# ATSAME51J18A register map
Vendor: Microchip Technology; Series: SAME51; File version: 0
CPU: CM4 r0p1, selectable endian, MPU, FPU, 3 interrupt priority bits
Registers are 32-bit, read-write, reset 0x0 unless marked. A register's access mark holds for its fields unless they carry their own. Offsets are from the block's base; [hi:lo] are bit positions; {n}, {i} and the like mark numbered series; 'fields as' and 'values as' point back to an identical list.

## SDHC0 — SD/MMC Host Controller
Base 0x45000000; register names take the prefix SDHC_
0x00 SSAR — SDMA System Address / Argument 2
  [31:0] ADDR — SDMA System Address
0x00 SSAR_CMD23_MODE (alternate view of SSAR) — SDMA System Address / Argument 2
  [31:0] ARG2 — Argument 2
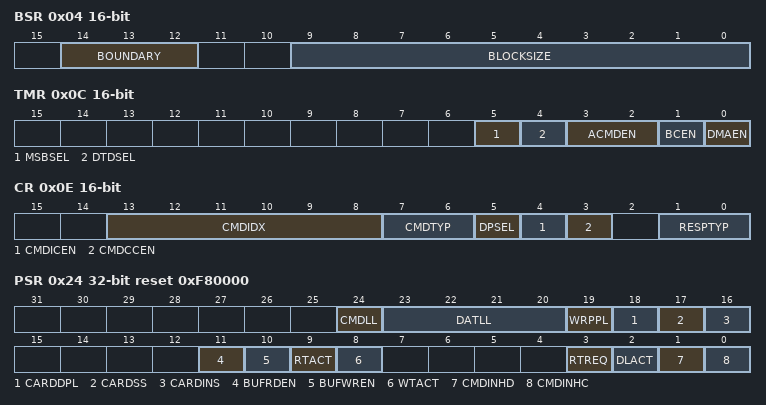
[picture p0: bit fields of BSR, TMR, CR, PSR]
0x04 BSR 16-bit — Block Size
  [14:12] BOUNDARY — SDMA Buffer Boundary
    0=4K (4k bytes); 1=8K (8k bytes); 2=16K (16k bytes); 3=32K (32k bytes); 4=64K (64k bytes); 5=128K (128k bytes); 6=256K (256k bytes); 7=512K (512k bytes)
  [9:0] BLOCKSIZE — Transfer Block Size
0x06 BCR 16-bit — Block Count
  [15:0] BCNT — Blocks Count for Current Transfer
0x08 ARG1R — Argument 1
  [31:0] ARG
0x0C TMR 16-bit — Transfer Mode
  [5] MSBSEL — Multi/Single Block Selection
    0=SINGLE (Single Block); 1=MULTIPLE (Multiple Block)
  [4] DTDSEL — Data Transfer Direction Selection
    0=WRITE (Write (Host to Card)); 1=READ (Read (Card to Host))
  [3:2] ACMDEN — Auto Command Enable
    0=DISABLED (Auto Command Disabled); 1=CMD12 (Auto CMD12 Enable); 2=CMD23 (Auto CMD23 Enable)
  [1] BCEN — Block Count Enable
    0=DISABLE; 1=ENABLE
  [0] DMAEN — DMA Enable
    0=DISABLE (No data transfer or Non DMA data transfer); 1=ENABLE (DMA data transfer)
0x0E CR 16-bit — Command
  [13:8] CMDIDX — Command Index
  [7:6] CMDTYP — Command Type
    0=NORMAL (Other commands); 1=SUSPEND (CMD52 for writing Bus Suspend in CCCR); 2=RESUME (CMD52 for writing Function Select in CCCR); 3=ABORT (CMD12, CMD52 for writing I/O Abort in CCCR)
  [5] DPSEL — Data Present Select
    0=NO_DATA (No Data Present); 1=DATA (Data Present)
  [4] CMDICEN — Command Index Check Enable
    0=DISABLE; 1=ENABLE
  [3] CMDCCEN — Command CRC Check Enable
    0=DISABLE; 1=ENABLE
  [1:0] RESPTYP — Response Type
    0=NONE (No response); 1=136_BIT (136-bit response); 2=48_BIT (48-bit response); 3=48_BIT_BUSY (48-bit response check busy after response)
{0x10+4i} RR[{i}] (i=0..3) ro — Response
  [31:0] CMDRESP — Command Response
0x20 BDPR — Buffer Data Port
  [31:0] BUFDATA — Buffer Data
0x24 PSR ro reset 0xF80000 — Present State
  [24] CMDLL — CMD Line Level
  [23:20] DATLL — DAT[3:0] Line Level
  [19] WRPPL — Write Protect Pin Level
    0=PROTECTED (Write protected (SDWP#=0)); 1=ENABLED (Write enabled (SDWP#=1))
  [18] CARDDPL — Card Detect Pin Level
    0=NO (No card present (SDCD#=1)); 1=YES (Card present (SDCD#=0))
  [17] CARDSS — Card State Stable
    0=NO (Reset or Debouncing); 1=YES (No Card or Insered)
  [16] CARDINS — Card Inserted
    0=NO (Reset or Debouncing or No Card); 1=YES (Card inserted)
  [11] BUFRDEN — Buffer Read Enable
    0=DISABLE (Read disable); 1=ENABLE (Read enable)
  [10] BUFWREN — Buffer Write Enable
    0=DISABLE (Write disable); 1=ENABLE (Write enable)
  [9] RTACT — Read Transfer Active
    0=NO (No valid data); 1=YES (Transferring data)
  [8] WTACT — Write Transfer Active
    0=NO (No valid data); 1=YES (Transferring data)
  [3] RTREQ — Re-Tuning Request
    0=OK (Fixed or well-tuned sampling clock); 1=REQUIRED (Sampling clock needs re-tuning)
  [2] DLACT — DAT Line Active
    0=INACTIVE (DAT Line Inactive); 1=ACTIVE (DAT Line Active)
  [1] CMDINHD — Command Inhibit (DAT)
    0=CAN (Can issue command which uses the DAT line); 1=CANNOT (Cannot issue command which uses the DAT line)
  [0] CMDINHC — Command Inhibit (CMD)
    0=CAN (Can issue command using only CMD line); 1=CANNOT (Cannot issue command)
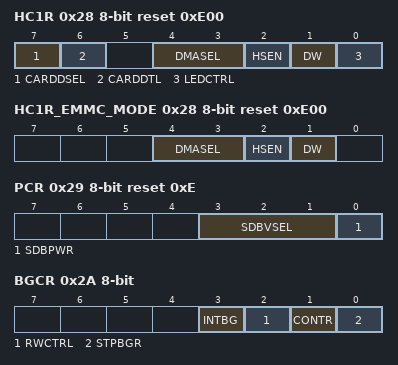
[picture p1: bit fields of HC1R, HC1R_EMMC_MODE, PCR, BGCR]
0x28 HC1R 8-bit reset 0xE00 — Host Control 1
  [7] CARDDSEL — Card Detect Signal Selection
    0=NORMAL (SDCD# is selected (for normal use)); 1=TEST (The Card Select Test Level is selected (for test purpose))
  [6] CARDDTL — Card Detect Test Level
    0=NO (No Card); 1=YES (Card Inserted)
  [4:3] DMASEL — DMA Select
    0=SDMA (SDMA is selected); 2=32BIT (32-bit Address ADMA2 is selected)
  [2] HSEN — High Speed Enable
    0=NORMAL (Normal Speed mode); 1=HIGH (High Speed mode)
  [1] DW — Data Width
    0=1BIT (1-bit mode); 1=4BIT (4-bit mode)
  [0] LEDCTRL — LED Control
    0=OFF (LED off); 1=ON (LED on)
0x28 HC1R_EMMC_MODE 8-bit reset 0xE00 (alternate view of HC1R) — Host Control 1
  [4:3] DMASEL — DMA Select
    values as HC1R.DMASEL
  [2] HSEN — High Speed Enable
    0=NORMAL (Normal Speed mode); 1=HIGH (High Speed mode)
  [1] DW — Data Width
    0=1BIT (1-bit mode); 1=4BIT (4-bit mode)
0x29 PCR 8-bit reset 0xE — Power Control
  [3:1] SDBVSEL — SD Bus Voltage Select
    5=1V8 (1.8V (Typ.)); 6=3V0 (3.0V (Typ.)); 7=3V3 (3.3V (Typ.))
  [0] SDBPWR — SD Bus Power
    0=OFF (Power off); 1=ON (Power on)
0x2A BGCR 8-bit — Block Gap Control
  [3] INTBG — Interrupt at Block Gap
    0=DISABLED; 1=ENABLED
  [2] RWCTRL — Read Wait Control
    0=DISABLE (Disable Read Wait Control); 1=ENABLE (Enable Read Wait Control)
  [1] CONTR — Continue Request
    0=GO_ON (Not affected); 1=RESTART
  [0] STPBGR — Stop at Block Gap Request
    0=TRANSFER; 1=STOP
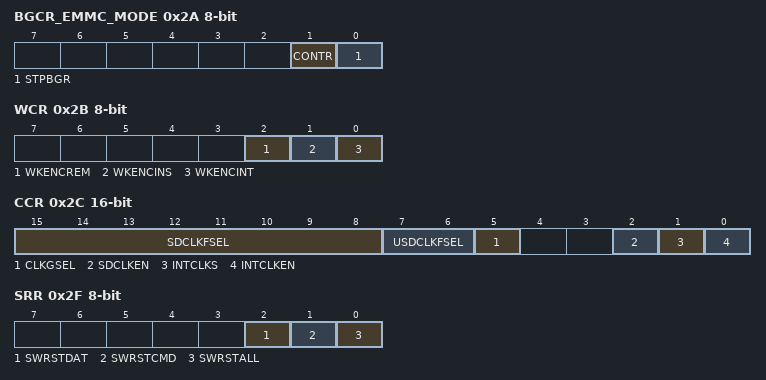
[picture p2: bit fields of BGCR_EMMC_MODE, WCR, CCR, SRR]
0x2A BGCR_EMMC_MODE 8-bit (alternate view of BGCR) — Block Gap Control
  [1] CONTR — Continue Request
    0=GO_ON (Not affected); 1=RESTART
  [0] STPBGR — Stop at Block Gap Request
    0=TRANSFER; 1=STOP
0x2B WCR 8-bit — Wakeup Control
  [all] fields
    0=DISABLE; 1=ENABLE
  [2] WKENCREM — Wakeup Event Enable on Card Removal
  [1] WKENCINS — Wakeup Event Enable on Card Insertion
  [0] WKENCINT — Wakeup Event Enable on Card Interrupt
0x2C CCR 16-bit — Clock Control
  [15:8] SDCLKFSEL — SDCLK Frequency Select
  [7:6] USDCLKFSEL — Upper Bits of SDCLK Frequency Select
  [5] CLKGSEL — Clock Generator Select
    0=DIV (Divided Clock Mode); 1=PROG (Programmable Clock Mode)
  [2] SDCLKEN — SD Clock Enable
    0=DISABLE; 1=ENABLE
  [1] INTCLKS — Internal Clock Stable
    0=NOT_READY; 1=READY
  [0] INTCLKEN — Internal Clock Enable
    0=OFF (Stop); 1=ON (Oscillate)
0x2E TCR 8-bit — Timeout Control
  [3:0] DTCVAL — Data Timeout Counter Value
0x2F SRR 8-bit — Software Reset
  [all] fields
    0=WORK; 1=RESET
  [2] SWRSTDAT — Software Reset For DAT Line
  [1] SWRSTCMD — Software Reset For CMD Line
  [0] SWRSTALL — Software Reset For All
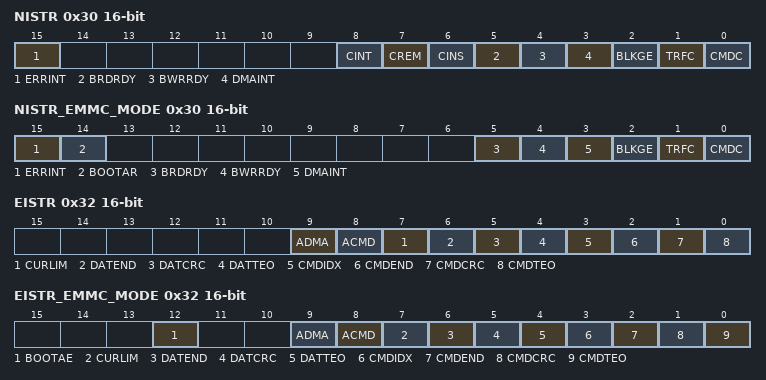
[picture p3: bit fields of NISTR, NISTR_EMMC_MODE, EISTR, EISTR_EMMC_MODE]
0x30 NISTR 16-bit — Normal Interrupt Status
  [15] ERRINT ro — Error Interrupt
    0=NO (No Error); 1=YES (Error)
  [8] CINT — Card Interrupt
    0=NO (No Card Interrupt); 1=YES (Generate Card Interrupt)
  [7] CREM write-1-clears — Card Removal
    0=NO (Card state stable or Debouncing); 1=YES (Card Removed)
  [6] CINS write-1-clears — Card Insertion
    0=NO (Card state stable or Debouncing); 1=YES (Card inserted)
  [5] BRDRDY write-1-clears — Buffer Read Ready
    0=NO (Not ready to read buffer); 1=YES (Ready to read buffer)
  [4] BWRRDY write-1-clears — Buffer Write Ready
    0=NO (Not ready to write buffer); 1=YES (Ready to write buffer)
  [3] DMAINT write-1-clears — DMA Interrupt
    0=NO (No DMA Interrupt); 1=YES (DMA Interrupt is generated)
  [2] BLKGE write-1-clears — Block Gap Event
    0=NO (No Block Gap Event); 1=STOP (Transaction stopped at block gap)
  [1] TRFC write-1-clears — Transfer Complete
    0=NO (Not complete); 1=YES (Command execution is completed)
  [0] CMDC write-1-clears — Command Complete
    0=NO (No command complete); 1=YES (Command complete)
0x30 NISTR_EMMC_MODE 16-bit (alternate view of NISTR) — Normal Interrupt Status
  [15] ERRINT ro — Error Interrupt
    0=NO (No Error); 1=YES (Error)
  [14] BOOTAR write-1-clears — Boot Acknowledge Received
  [5] BRDRDY write-1-clears — Buffer Read Ready
    values as NISTR.BRDRDY
  [4] BWRRDY write-1-clears — Buffer Write Ready
    values as NISTR.BWRRDY
  [3] DMAINT write-1-clears — DMA Interrupt
    0=NO (No DMA Interrupt); 1=YES (DMA Interrupt is generated)
  [2] BLKGE write-1-clears — Block Gap Event
    values as NISTR.BLKGE
  [1] TRFC write-1-clears — Transfer Complete
    0=NO (Not complete); 1=YES (Command execution is completed)
  [0] CMDC write-1-clears — Command Complete
    0=NO (No command complete); 1=YES (Command complete)
0x32 EISTR 16-bit — Error Interrupt Status
  [9] ADMA write-1-clears — ADMA Error
    0=NO (No Error); 1=YES (Error)
  [8] ACMD write-1-clears — Auto CMD Error
    0=NO (No Error); 1=YES (Error)
  [7] CURLIM write-1-clears — Current Limit Error
    0=NO (No Error); 1=YES (Power Fail)
  [6] DATEND write-1-clears — Data End Bit Error
    0=NO (No Error); 1=YES (Error)
  [5] DATCRC write-1-clears — Data CRC Error
    0=NO (No Error); 1=YES (Error)
  [4] DATTEO write-1-clears — Data Timeout Error
    0=NO (No Error); 1=YES (Timeout)
  [3] CMDIDX write-1-clears — Command Index Error
    0=NO (No Error); 1=YES (Error)
  [2] CMDEND write-1-clears — Command End Bit Error
    0=NO (No error); 1=YES (End Bit Error Generated)
  [1] CMDCRC write-1-clears — Command CRC Error
    0=NO (No Error); 1=YES (CRC Error Generated)
  [0] CMDTEO write-1-clears — Command Timeout Error
    0=NO (No Error); 1=YES (Timeout)
0x32 EISTR_EMMC_MODE 16-bit (alternate view of EISTR) — Error Interrupt Status
  [12] BOOTAE write-1-clears — Boot Acknowledge Error
    0=FIFO contains at least one byte; 1=FIFO is empty
  [9] ADMA write-1-clears — ADMA Error
    0=NO (No Error); 1=YES (Error)
  [8] ACMD write-1-clears — Auto CMD Error
    0=NO (No Error); 1=YES (Error)
  [7] CURLIM write-1-clears — Current Limit Error
    0=NO (No Error); 1=YES (Power Fail)
  [6] DATEND write-1-clears — Data End Bit Error
    0=NO (No Error); 1=YES (Error)
  [5] DATCRC write-1-clears — Data CRC Error
    0=NO (No Error); 1=YES (Error)
  [4] DATTEO write-1-clears — Data Timeout Error
    0=NO (No Error); 1=YES (Timeout)
  [3] CMDIDX write-1-clears — Command Index Error
    0=NO (No Error); 1=YES (Error)
  [2] CMDEND write-1-clears — Command End Bit Error
    0=NO (No error); 1=YES (End Bit Error Generated)
  [1] CMDCRC write-1-clears — Command CRC Error
    0=NO (No Error); 1=YES (CRC Error Generated)
  [0] CMDTEO write-1-clears — Command Timeout Error
    0=NO (No Error); 1=YES (Timeout)
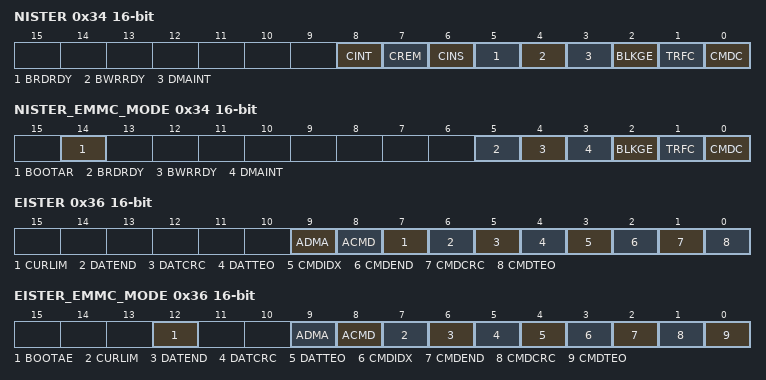
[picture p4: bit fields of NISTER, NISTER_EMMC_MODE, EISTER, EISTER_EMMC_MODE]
0x34 NISTER 16-bit — Normal Interrupt Status Enable
  [all] fields
    0=MASKED; 1=ENABLED
  [8] CINT — Card Interrupt Status Enable
  [7] CREM — Card Removal Status Enable
  [6] CINS — Card Insertion Status Enable
  [5] BRDRDY — Buffer Read Ready Status Enable
  [4] BWRRDY — Buffer Write Ready Status Enable
  [3] DMAINT — DMA Interrupt Status Enable
  [2] BLKGE — Block Gap Event Status Enable
  [1] TRFC — Transfer Complete Status Enable
  [0] CMDC — Command Complete Status Enable
0x34 NISTER_EMMC_MODE 16-bit (alternate view of NISTER) — Normal Interrupt Status Enable
  [14] BOOTAR — Boot Acknowledge Received Status Enable
  [5] BRDRDY — Buffer Read Ready Status Enable
    0=MASKED; 1=ENABLED
  [4] BWRRDY — Buffer Write Ready Status Enable
    0=MASKED; 1=ENABLED
  [3] DMAINT — DMA Interrupt Status Enable
    0=MASKED; 1=ENABLED
  [2] BLKGE — Block Gap Event Status Enable
    0=MASKED; 1=ENABLED
  [1] TRFC — Transfer Complete Status Enable
    0=MASKED; 1=ENABLED
  [0] CMDC — Command Complete Status Enable
    0=MASKED; 1=ENABLED
0x36 EISTER 16-bit — Error Interrupt Status Enable
  [all] fields
    0=MASKED; 1=ENABLED
  [9] ADMA — ADMA Error Status Enable
  [8] ACMD — Auto CMD Error Status Enable
  [7] CURLIM — Current Limit Error Status Enable
  [6] DATEND — Data End Bit Error Status Enable
  [5] DATCRC — Data CRC Error Status Enable
  [4] DATTEO — Data Timeout Error Status Enable
  [3] CMDIDX — Command Index Error Status Enable
  [2] CMDEND — Command End Bit Error Status Enable
  [1] CMDCRC — Command CRC Error Status Enable
  [0] CMDTEO — Command Timeout Error Status Enable
0x36 EISTER_EMMC_MODE 16-bit (alternate view of EISTER) — Error Interrupt Status Enable
  [12] BOOTAE — Boot Acknowledge Error Status Enable
  [9] ADMA — ADMA Error Status Enable
    0=MASKED; 1=ENABLED
  [8] ACMD — Auto CMD Error Status Enable
    0=MASKED; 1=ENABLED
  [7] CURLIM — Current Limit Error Status Enable
    0=MASKED; 1=ENABLED
  [6] DATEND — Data End Bit Error Status Enable
    0=MASKED; 1=ENABLED
  [5] DATCRC — Data CRC Error Status Enable
    0=MASKED; 1=ENABLED
  [4] DATTEO — Data Timeout Error Status Enable
    0=MASKED; 1=ENABLED
  [3] CMDIDX — Command Index Error Status Enable
    0=MASKED; 1=ENABLED
  [2] CMDEND — Command End Bit Error Status Enable
    0=MASKED; 1=ENABLED
  [1] CMDCRC — Command CRC Error Status Enable
    0=MASKED; 1=ENABLED
  [0] CMDTEO — Command Timeout Error Status Enable
    0=MASKED; 1=ENABLED
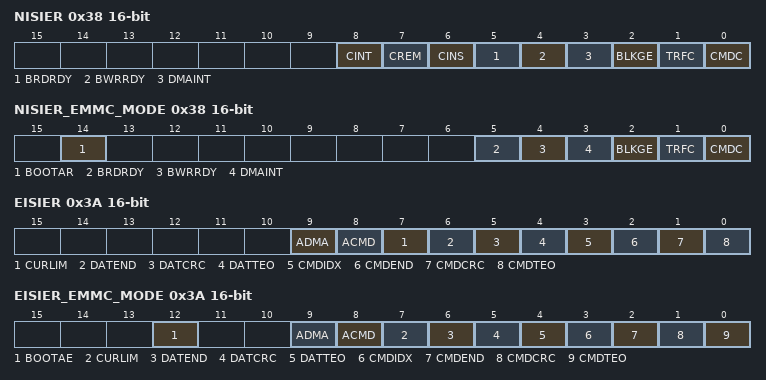
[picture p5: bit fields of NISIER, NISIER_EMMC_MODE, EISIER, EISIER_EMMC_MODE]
0x38 NISIER 16-bit — Normal Interrupt Signal Enable
  [all] fields
    0=MASKED; 1=ENABLED
  [8] CINT — Card Interrupt Signal Enable
  [7] CREM — Card Removal Signal Enable
  [6] CINS — Card Insertion Signal Enable
  [5] BRDRDY — Buffer Read Ready Signal Enable
  [4] BWRRDY — Buffer Write Ready Signal Enable
  [3] DMAINT — DMA Interrupt Signal Enable
  [2] BLKGE — Block Gap Event Signal Enable
  [1] TRFC — Transfer Complete Signal Enable
  [0] CMDC — Command Complete Signal Enable
0x38 NISIER_EMMC_MODE 16-bit (alternate view of NISIER) — Normal Interrupt Signal Enable
  [14] BOOTAR — Boot Acknowledge Received Signal Enable
  [5] BRDRDY — Buffer Read Ready Signal Enable
    0=MASKED; 1=ENABLED
  [4] BWRRDY — Buffer Write Ready Signal Enable
    0=MASKED; 1=ENABLED
  [3] DMAINT — DMA Interrupt Signal Enable
    0=MASKED; 1=ENABLED
  [2] BLKGE — Block Gap Event Signal Enable
    0=MASKED; 1=ENABLED
  [1] TRFC — Transfer Complete Signal Enable
    0=MASKED; 1=ENABLED
  [0] CMDC — Command Complete Signal Enable
    0=MASKED; 1=ENABLED
0x3A EISIER 16-bit — Error Interrupt Signal Enable
  [all] fields
    0=MASKED; 1=ENABLED
  [9] ADMA — ADMA Error Signal Enable
  [8] ACMD — Auto CMD Error Signal Enable
  [7] CURLIM — Current Limit Error Signal Enable
  [6] DATEND — Data End Bit Error Signal Enable
  [5] DATCRC — Data CRC Error Signal Enable
  [4] DATTEO — Data Timeout Error Signal Enable
  [3] CMDIDX — Command Index Error Signal Enable
  [2] CMDEND — Command End Bit Error Signal Enable
  [1] CMDCRC — Command CRC Error Signal Enable
  [0] CMDTEO — Command Timeout Error Signal Enable
0x3A EISIER_EMMC_MODE 16-bit (alternate view of EISIER) — Error Interrupt Signal Enable
  [12] BOOTAE — Boot Acknowledge Error Signal Enable
  [9] ADMA — ADMA Error Signal Enable
    0=MASKED; 1=ENABLED
  [8] ACMD — Auto CMD Error Signal Enable
    0=MASKED; 1=ENABLED
  [7] CURLIM — Current Limit Error Signal Enable
    0=MASKED; 1=ENABLED
  [6] DATEND — Data End Bit Error Signal Enable
    0=MASKED; 1=ENABLED
  [5] DATCRC — Data CRC Error Signal Enable
    0=MASKED; 1=ENABLED
  [4] DATTEO — Data Timeout Error Signal Enable
    0=MASKED; 1=ENABLED
  [3] CMDIDX — Command Index Error Signal Enable
    0=MASKED; 1=ENABLED
  [2] CMDEND — Command End Bit Error Signal Enable
    0=MASKED; 1=ENABLED
  [1] CMDCRC — Command CRC Error Signal Enable
    0=MASKED; 1=ENABLED
  [0] CMDTEO — Command Timeout Error Signal Enable
    0=MASKED; 1=ENABLED
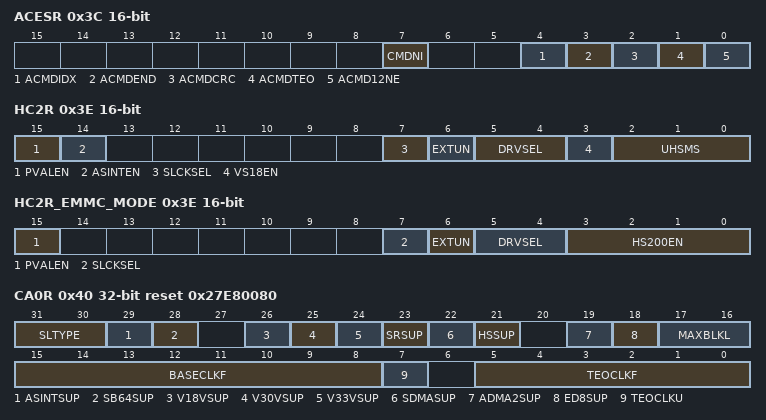
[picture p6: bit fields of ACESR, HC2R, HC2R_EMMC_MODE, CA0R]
0x3C ACESR 16-bit ro — Auto CMD Error Status
  [7] CMDNI — Command not Issued By Auto CMD12 Error
    0=OK (No error); 1=NOT_ISSUED
  [4] ACMDIDX — Auto CMD Index Error
    0=NO (No error); 1=YES (Error)
  [3] ACMDEND — Auto CMD End Bit Error
    0=NO (No error); 1=YES (End Bit Error Generated)
  [2] ACMDCRC — Auto CMD CRC Error
    0=NO (No error); 1=YES (CRC Error Generated)
  [1] ACMDTEO — Auto CMD Timeout Error
    0=NO (No error); 1=YES (Timeout)
  [0] ACMD12NE — Auto CMD12 Not Executed
    0=EXEC (Executed); 1=NOT_EXEC (Not executed)
0x3E HC2R 16-bit — Host Control 2
  [15] PVALEN — Preset Value Enable
    0=HOST (SDCLK and Driver Strength are controlled by Host Controller); 1=AUTO (Automatic Selection by Preset Value is Enabled)
  [14] ASINTEN — Asynchronous Interrupt Enable
    0=DISABLED; 1=ENABLED
  [7] SLCKSEL — Sampling Clock Select
    0=FIXED (Fixed clock is used to sample data); 1=TUNED (Tuned clock is used to sample data)
  [6] EXTUN — Execute Tuning
    0=NO (Not Tuned or Tuning Completed); 1=REQUESTED (Execute Tuning)
  [5:4] DRVSEL — Driver Strength Select
    0=B (Driver Type B is Selected (Default)); 1=A (Driver Type A is Selected); 2=C (Driver Type C is Selected); 3=D (Driver Type D is Selected)
  [3] VS18EN — 1.8V Signaling Enable
    0=S33V (3.3V Signaling); 1=S18V (1.8V Signaling)
  [2:0] UHSMS — UHS Mode Select
    0=SDR12; 1=SDR25; 2=SDR50; 3=SDR104; 4=DDR50
0x3E HC2R_EMMC_MODE 16-bit (alternate view of HC2R) — Host Control 2
  [15] PVALEN — Preset Value Enable
    values as HC2R.PVALEN
  [7] SLCKSEL — Sampling Clock Select
    values as HC2R.SLCKSEL
  [6] EXTUN — Execute Tuning
    values as HC2R.EXTUN
  [5:4] DRVSEL — Driver Strength Select
    values as HC2R.DRVSEL
  [3:0] HS200EN — HS200 Mode Enable
    0=SDR12; 1=SDR25; 2=SDR50; 3=SDR104; 4=DDR50
0x40 CA0R ro reset 0x27E80080 — Capabilities 0
  [31:30] SLTYPE — Slot Type
    0=REMOVABLE (Removable Card Slot); 1=EMBEDDED (Embedded Slot for One Device)
  [29] ASINTSUP — Asynchronous Interrupt Support
    0=NO (Asynchronous Interrupt not Supported); 1=YES (Asynchronous Interrupt supported)
  [28] SB64SUP — 64-Bit System Bus Support
    0=NO (32-bit Address Descriptors and System Bus); 1=YES (64-bit Address Descriptors and System Bus)
  [26] V18VSUP — Voltage Support 1.8V
    0=NO (1.8V Not Supported); 1=YES (1.8V Supported)
  [25] V30VSUP — Voltage Support 3.0V
    0=NO (3.0V Not Supported); 1=YES (3.0V Supported)
  [24] V33VSUP — Voltage Support 3.3V
    0=NO (3.3V Not Supported); 1=YES (3.3V Supported)
  [23] SRSUP — Suspend/Resume Support
    0=NO (Suspend/Resume not Supported); 1=YES (Suspend/Resume Supported)
  [22] SDMASUP — SDMA Support
    0=NO (SDMA not Supported); 1=YES (SDMA Supported)
  [21] HSSUP — High Speed Support
    0=NO (High Speed not Supported); 1=YES (High Speed Supported)
  [19] ADMA2SUP — ADMA2 Support
    0=NO (ADMA2 not Supported); 1=YES (ADMA2 Supported)
  [18] ED8SUP — 8-bit Support for Embedded Device
    0=NO (8-bit Bus Width not Supported); 1=YES (8-bit Bus Width Supported)
  [17:16] MAXBLKL — Max Block Length
    0=512 bytes; 1=1024 bytes; 2=2048 bytes
  [15:8] BASECLKF — Base Clock Frequency
    0=OTHER (Get information via another method)
  [7] TEOCLKU — Timeout Clock Unit
    0=KHZ; 1=MHZ
  [5:0] TEOCLKF — Timeout Clock Frequency
    0=OTHER (Get information via another method)
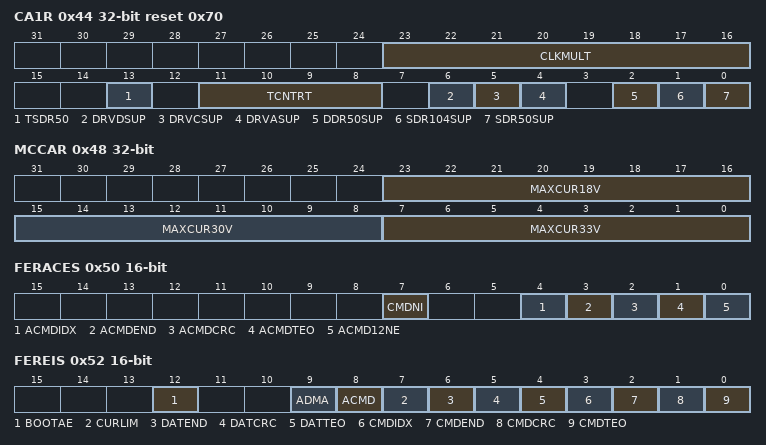
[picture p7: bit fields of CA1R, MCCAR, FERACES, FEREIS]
0x44 CA1R ro reset 0x70 — Capabilities 1
  [23:16] CLKMULT — Clock Multiplier
    0=NO (Clock Multiplier is Not Supported)
  [13] TSDR50 — Use Tuning for SDR50
    0=NO (SDR50 does not require tuning); 1=YES (SDR50 requires tuning)
  [11:8] TCNTRT — Timer Count for Re-Tuning
    0=DISABLED (Re-Tuning Timer disabled); 1=1S (1 second); 2=2S (2 seconds); 3=4S (4 seconds); 4=8S (8 seconds); 5=16S (16 seconds); 6=32S (32 seconds); 7=64S (64 seconds); 8=128S (128 seconds); 9=256S (256 seconds); 10=512S (512 seconds); 11=1024S (1024 seconds); 15=OTHER (Get information from other source)
  [6] DRVDSUP — Driver Type D Support
    0=NO (Driver Type D is Not Supported); 1=YES (Driver Type D is Supported)
  [5] DRVCSUP — Driver Type C Support
    0=NO (Driver Type C is Not Supported); 1=YES (Driver Type C is Supported)
  [4] DRVASUP — Driver Type A Support
    0=NO (Driver Type A is Not Supported); 1=YES (Driver Type A is Supported)
  [2] DDR50SUP — DDR50 Support
    0=NO (DDR50 is Not Supported); 1=YES (DDR50 is Supported)
  [1] SDR104SUP — SDR104 Support
    0=NO (SDR104 is Not Supported); 1=YES (SDR104 is Supported)
  [0] SDR50SUP — SDR50 Support
    0=NO (SDR50 is Not Supported); 1=YES (SDR50 is Supported)
0x48 MCCAR ro — Maximum Current Capabilities
  [all] fields
    0=OTHER (Get information via another method); 1=4MA; 2=8MA; 3=12MA
  [23:16] MAXCUR18V — Maximum Current for 1.8V
  [15:8] MAXCUR30V — Maximum Current for 3.0V
  [7:0] MAXCUR33V — Maximum Current for 3.3V
0x50 FERACES 16-bit wo — Force Event for Auto CMD Error Status
  [all] fields
    0=NO (No Interrupt); 1=YES (Interrupt is generated)
  [7] CMDNI — Force Event for Command Not Issued By Auto CMD12 Error
  [4] ACMDIDX — Force Event for Auto CMD Index Error
  [3] ACMDEND — Force Event for Auto CMD End Bit Error
  [2] ACMDCRC — Force Event for Auto CMD CRC Error
  [1] ACMDTEO — Force Event for Auto CMD Timeout Error
  [0] ACMD12NE — Force Event for Auto CMD12 Not Executed
0x52 FEREIS 16-bit wo — Force Event for Error Interrupt Status
  [all] fields
    0=NO (No Interrupt); 1=YES (Interrupt is generated)
  [12] BOOTAE — Force Event for Boot Acknowledge Error
  [9] ADMA — Force Event for ADMA Error
  [8] ACMD — Force Event for Auto CMD Error
  [7] CURLIM — Force Event for Current Limit Error
  [6] DATEND — Force Event for Data End Bit Error
  [5] DATCRC — Force Event for Data CRC Error
  [4] DATTEO — Force Event for Data Timeout Error
  [3] CMDIDX — Force Event for Command Index Error
  [2] CMDEND — Force Event for Command End Bit Error
  [1] CMDCRC — Force Event for Command CRC Error
  [0] CMDTEO — Force Event for Command Timeout Error
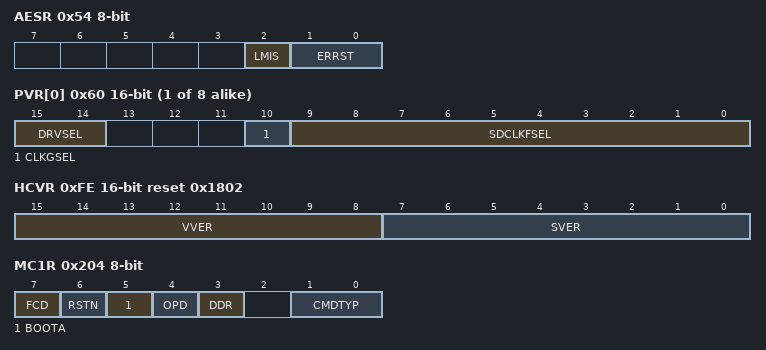
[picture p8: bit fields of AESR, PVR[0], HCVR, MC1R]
0x54 AESR 8-bit ro — ADMA Error Status
  [2] LMIS — ADMA Length Mismatch Error
    0=NO (No Error); 1=YES (Error)
  [1:0] ERRST — ADMA Error State
    0=STOP (ST_STOP (Stop DMA)); 1=FDS (ST_FDS (Fetch Descriptor)); 3=TFR (ST_TFR (Transfer Data))
{0x58+4i} ASAR[{i}] (i=0..0) — ADMA System Address n
  [31:0] ADMASA — ADMA System Address
{0x60+2i} PVR[{i}] (i=0..7) 16-bit — Preset Value n
  [15:14] DRVSEL — Driver Strength Select Value for Initialization
    0=B (Driver Type B is Selected); 1=A (Driver Type A is Selected); 2=C (Driver Type C is Selected); 3=D (Driver Type D is Selected)
  [10] CLKGSEL — Clock Generator Select Value for Initialization
    0=DIV (Host Controller Ver2.00 Compatible Clock Generator (Divider)); 1=PROG (Programmable Clock Generator)
  [9:0] SDCLKFSEL — SDCLK Frequency Select Value for Initialization
0xFC SISR 16-bit ro reset 0x20000 — Slot Interrupt Status
  [0] INTSSL — Interrupt Signal for Each Slot
0xFE HCVR 16-bit ro reset 0x1802 — Host Controller Version
  [15:8] VVER — Vendor Version
  [7:0] SVER — Spec Version
0x204 MC1R 8-bit — MMC Control 1
  [7] FCD — e.MMC Force Card Detect
  [6] RSTN — e.MMC Reset Signal
  [5] BOOTA — e.MMC Boot Acknowledge Enable
  [4] OPD — e.MMC Open Drain Mode
  [3] DDR — e.MMC HSDDR Mode
  [1:0] CMDTYP — e.MMC Command Type
    0=NORMAL (Not a MMC specific command); 1=WAITIRQ (Wait IRQ Command); 2=STREAM (Stream Command); 3=BOOT (Boot Command)
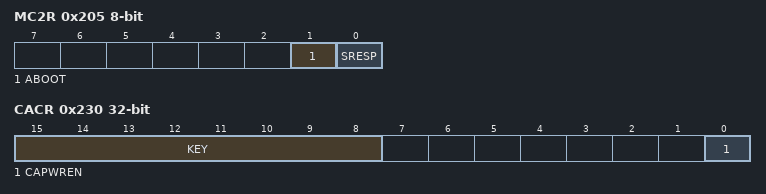
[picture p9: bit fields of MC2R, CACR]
0x205 MC2R 8-bit wo — MMC Control 2
  [1] ABOOT — e.MMC Abort Boot
  [0] SRESP — e.MMC Abort Wait IRQ
0x208 ACR — AHB Control
  [1:0] BMAX — AHB Maximum Burst
    0=INCR16; 1=INCR8; 2=INCR4; 3=SINGLE
0x20C CC2R — Clock Control 2
  [0] FSDCLKD — Force SDCK Disabled
    0=NOEFFECT; 1=DISABLE (SDCLK can be stopped at any time after DATA transfer.SDCLK enable forcing for 8 SDCLK cycles is disabled)
0x230 CACR — Capabilities Control
  [15:8] KEY — Key (0x46)
  [0] CAPWREN — Capabilities Registers Write Enable (Required to write the correct frequencies in the Capabilities Registers)
0x234 DBGR 8-bit — Debug
  [0] NIDBG — Non-intrusive debug enable
    0=IDBG (Debugging is intrusive (reads of BDPR from debugger are considered and increment the internal buffer pointer)); 1=NIDBG (Debugging is not intrusive (reads of BDPR from debugger are discarded and do not increment the internal buffer pointer))
